# d_ip_ana_test_annex_syn: IP-XACT component
VLNV Origen:Origen:d_ip_ana_test_annex_syn:

## Address spaces and blocks
RegisterMap.: base 0x40000000, range 8, width 32

## Registers
Registers are 16-bit, read-write, reset 0x8000 unless marked. A register's access mark holds for its fields unless they carry their own. Offsets are from the block's base; lines under a group give offsets from that group; [hi:lo] are bit positions; {n}, {i} and the like mark numbered series; 'fields as' and 'values as' point back to an identical list; <NAME> marks a mode.

## RegisterMap.block0
Base 0x40000000
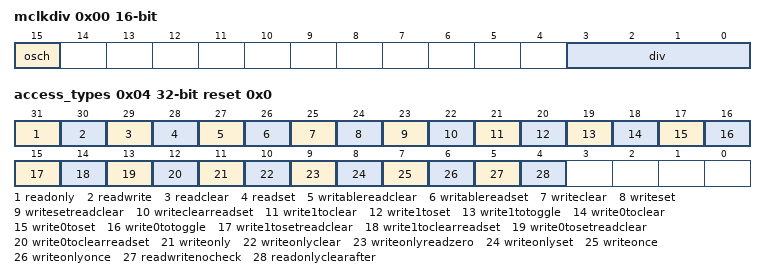
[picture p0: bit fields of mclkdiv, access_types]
0x00 mclkdiv — MPU Clock Divider Register
  [15] osch — Oscillator (Hi)
    0=Clock is the externally supplied bus clock bus_clk; 1=Clock is the internal oscillator from the hardblock
  [3:0] div — Divider Value
0x04 access_types 32-bit reset 0x0 — Access Type Test Register
  [31] readonly ro, [30] readwrite, [29] readclear rc, [28] readset rs, [27] writablereadclear wrc, [26] writablereadset wrs, [25] writeclear wc, [24] writeset ws, [23] writesetreadclear wsrc, [22] writeclearreadset wcrs, [21] write1toclear w1c, [20] write1toset w1s, [19] write1totoggle w1t, [18] write0toclear w0c, [17] write0toset w0s, [16] write0totoggle w0t, [15] write1tosetreadclear w1src, [14] write1toclearreadset w1crs, [13] write0tosetreadclear w0src, [12] write0toclearreadset w0crs, [11] writeonly wo, [10] writeonlyclear woc, [9] writeonlyreadzero worz, [8] writeonlyset wos, [7] writeonce w1, [6] writeonlyonce wo1, [5] readwritenocheck dc, [4] readonlyclearafter rowz
